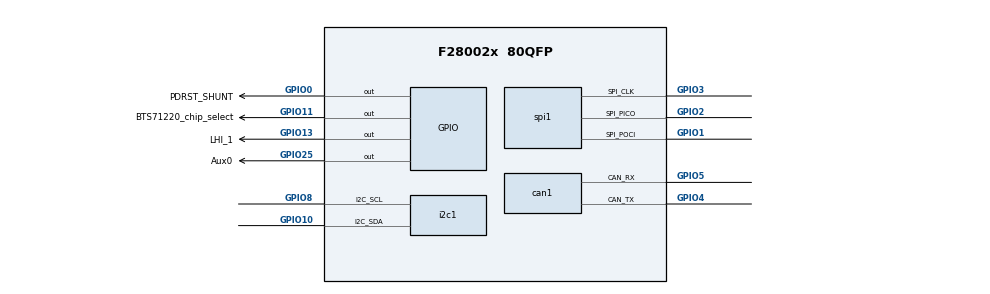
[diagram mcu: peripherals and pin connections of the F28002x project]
/**
 * @cliArgs --device "F28002x" --package "80QFP" --part "F28002x_80QFP" --context "system" --product "C2000WARE@5.00.00.00"
 * @versions {"tool":"1.16.1+2960"}
 */

/**
 * Import the modules used in this configuration.
 */
const adc       = scripting.addModule("/driverlib/adc.js", {}, false);
const adc1      = adc.addInstance();
const analog    = scripting.addModule("/driverlib/analog.js", {}, false);
const analog1   = analog.addInstance();
const asysctl   = scripting.addModule("/driverlib/asysctl.js");
const can       = scripting.addModule("/driverlib/can.js", {}, false);
const can1      = can.addInstance();
const cputimer  = scripting.addModule("/driverlib/cputimer.js", {}, false);
const cputimer1 = cputimer.addInstance();
const gpio      = scripting.addModule("/driverlib/gpio.js", {}, false);
const gpio1     = gpio.addInstance();
const gpio2     = gpio.addInstance();
const gpio3     = gpio.addInstance();
const gpio4     = gpio.addInstance();
const i2c       = scripting.addModule("/driverlib/i2c.js", {}, false);
const i2c1      = i2c.addInstance();
const spi       = scripting.addModule("/driverlib/spi.js", {}, false);
const spi1      = spi.addInstance();

/**
 * Write custom configuration values to the imported modules.
 */
adc1.$name              = "myADC0";
adc1.adcClockPrescaler  = "ADC_CLK_DIV_2_0";
adc1.enabledSOCs        = ["ADC_SOC_NUMBER0"];
adc1.soc0Channel        = "ADC_CH_ADCIN5";
adc1.soc0SampleWindow   = 8;
adc1.interruptPulseMode = "ADC_PULSE_END_OF_CONV";
adc1.enableInterrupt1   = true;
adc1.enabledInts        = ["ADC_INT_NUMBER1"];

analog1.$name                      = "myANALOGPinMux0";
analog1.useInterfacePins           = ["A5/C2"];
adc1.analog                        = analog1;
analog1.useCase                    = "CUSTOM";
analog1.analog.$assign             = "ANALOG";
analog1.analog["a5/c2Pin"].$assign = "A5/C2";

asysctl.analogReference        = "INTERNAL";
asysctl.analogReferenceVoltage = "1P65";

can1.$name                 = "myCAN0";
can1.msgObjsUsed           = [1,2];
can1.can.can_rxPin.$assign = "GPIO5";
can1.can.can_txPin.$assign = "GPIO4";
can1.msgObj1.$name         = "msgObj0";
can1.msgObj1.msgID         = 10;
can1.msgObj1.msgType       = "CAN_MSG_OBJ_TYPE_TX";
can1.msgObj1.msgLen        = 8;
can1.msgObj2.$name         = "msgObj1";
can1.msgObj2.msgID         = 11;

cputimer1.$name          = "myCPUTIMER0";
cputimer1.startTimer     = true;
cputimer1.timerPrescaler = 9999;
cputimer1.timerPeriod    = 1000000;

gpio1.$name             = "BTS71220_chip_select";
gpio1.direction         = "GPIO_DIR_MODE_OUT";
gpio1.writeInitialValue = true;
gpio1.initialValue      = 1;
gpio1.gpioPin.$assign   = "GPIO11";

gpio2.$name             = "LHI_1";
gpio2.direction         = "GPIO_DIR_MODE_OUT";
gpio2.writeInitialValue = true;
gpio2.gpioPin.$assign   = "GPIO13";

gpio3.$name             = "PDRST_SHUNT";
gpio3.direction         = "GPIO_DIR_MODE_OUT";
gpio3.writeInitialValue = true;
gpio3.initialValue      = 1;
gpio3.gpioPin.$assign   = "GPIO0";

gpio4.$name             = "Aux0";
gpio4.direction         = "GPIO_DIR_MODE_OUT";
gpio4.writeInitialValue = true;
gpio4.gpioPin.$assign   = "GPIO25";

i2c1.$name                  = "myI2C0";
i2c1.bitCount               = "I2C_BITCOUNT_8";
i2c1.targetAddress          = 0x51;
i2c1.useInterfacePins       = ["I2C@_SCL","I2C@_SDA"];
i2c1.useCase                = "CUSTOM";
i2c1.dataCount              = 2;
i2c1.bitRate                = 100000;
i2c1.enabledInterrupts      = ["I2C_INT_RX_DATA_RDY"];
i2c1.useInterrupts          = false;
i2c1.emulationMode          = "I2C_EMULATION_FREE_RUN";
i2c1.i2c.i2c_sdaPin.$assign = "GPIO10";
i2c1.i2c.i2c_sclPin.$assign = "GPIO8";

spi1.$name                   = "mySPI0";
spi1.bitRate                 = 1000000;
spi1.useInterrupts           = false;
spi1.useCase                 = "CUSTOM";
spi1.useInterfacePins        = ["SPI@_CLK","SPI@_SIMO","SPI@_SOMI"];
spi1.mode                    = "SPI_MODE_CONTROLLER";
spi1.dataWidth               = "8";
spi1.emulationMode           = "SPI_EMULATION_FREE_RUN";
spi1.useFifo                 = false;
spi1.spi.$assign             = "SPIA";
spi1.spi.spi_picoPin.$assign = "GPIO2";
spi1.spi.spi_pociPin.$assign = "GPIO1";
spi1.spi.spi_clkPin.$assign  = "GPIO3";

/**
 * Pinmux solution for unlocked pins/peripherals. This ensures that minor changes to the automatic solver in a future
 * version of the tool will not impact the pinmux you originally saw.  These lines can be completely deleted in order to
 * re-solve from scratch.
 */
can1.can.$suggestSolution = "CANA";
i2c1.i2c.$suggestSolution = "I2CA";
